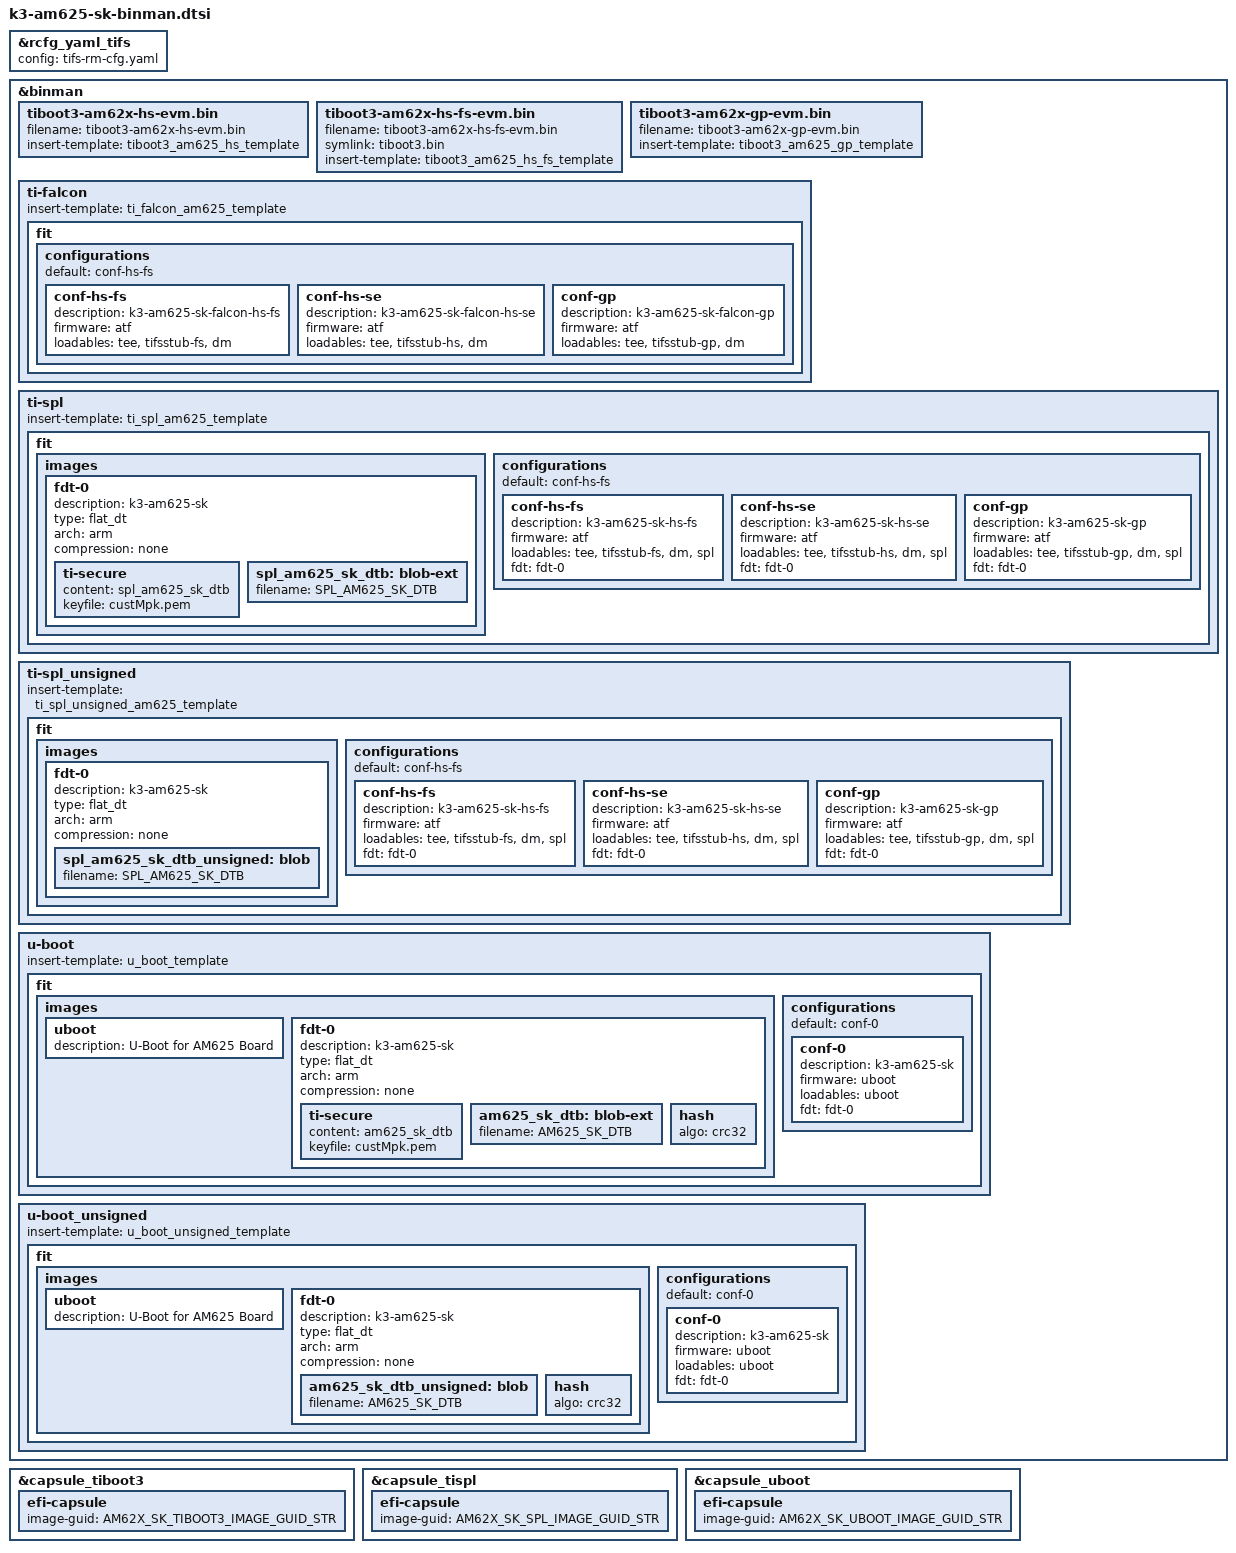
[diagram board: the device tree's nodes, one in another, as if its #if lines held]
// SPDX-License-Identifier: GPL-2.0
/*
 * Copyright (C) 2022-2023 Texas Instruments Incorporated - https://www.ti.com/
 */

#include "k3-am625-binman.dtsi"

#ifdef CONFIG_TARGET_AM625_R5_EVM

&rcfg_yaml_tifs {
	config = "tifs-rm-cfg.yaml";
};

&binman {
	tiboot3-am62x-hs-evm.bin {
		filename = "tiboot3-am62x-hs-evm.bin";
		insert-template = <&tiboot3_am625_hs_template>;
	};
	tiboot3-am62x-hs-fs-evm.bin {
		filename = "tiboot3-am62x-hs-fs-evm.bin";
		symlink = "tiboot3.bin";
		insert-template = <&tiboot3_am625_hs_fs_template>;
	};
	tiboot3-am62x-gp-evm.bin {
		filename = "tiboot3-am62x-gp-evm.bin";
		insert-template = <&tiboot3_am625_gp_template>;
	};
};

#include "k3-binman-capsule-r5.dtsi"

// Capsule update GUIDs in string form.  See am62x_evm.h
#define AM62X_SK_TIBOOT3_IMAGE_GUID_STR "abcb83d2-9cb6-4351-b8f1-6494bbe3700a"

&capsule_tiboot3 {
	efi-capsule {
		image-guid = AM62X_SK_TIBOOT3_IMAGE_GUID_STR;
	};
};

#endif

#ifdef CONFIG_TARGET_AM625_A53_EVM

#define SPL_AM625_SK_DTB "spl/dts/ti/k3-am625-sk.dtb"
#define AM625_SK_DTB "u-boot.dtb"

&binman {
	ti-falcon {
		insert-template = <&ti_falcon_am625_template>;
		fit {
			configurations {
				default = "conf-hs-fs";
				conf-hs-fs {
					description = "k3-am625-sk-falcon-hs-fs";
					firmware = "atf";
					loadables = "tee", "tifsstub-fs", "dm";
				};
				conf-hs-se {
					description = "k3-am625-sk-falcon-hs-se";
					firmware = "atf";
					loadables = "tee", "tifsstub-hs", "dm";
				};
				conf-gp {
					description = "k3-am625-sk-falcon-gp";
					firmware = "atf";
					loadables = "tee", "tifsstub-gp", "dm";
				};
			};
		};
	};

	ti-spl {
		insert-template = <&ti_spl_am625_template>;
		fit {
			images {
				fdt-0 {
					description = "k3-am625-sk";
					type = "flat_dt";
					arch = "arm";
					compression = "none";
					ti-secure {
						content = <&spl_am625_sk_dtb>;
						keyfile = "custMpk.pem";
					};
					spl_am625_sk_dtb: blob-ext {
						filename = SPL_AM625_SK_DTB;
					};
				};
			};
			configurations {
				default = "conf-hs-fs";
				conf-hs-fs {
					description = "k3-am625-sk-hs-fs";
					firmware = "atf";
					loadables = "tee", "tifsstub-fs", "dm", "spl";
					fdt = "fdt-0";
				};
				conf-hs-se {
					description = "k3-am625-sk-hs-se";
					firmware = "atf";
					loadables = "tee", "tifsstub-hs", "dm", "spl";
					fdt = "fdt-0";
				};
				conf-gp {
					description = "k3-am625-sk-gp";
					firmware = "atf";
					loadables = "tee", "tifsstub-gp", "dm", "spl";
					fdt = "fdt-0";
				};
			};
		};
	};

	ti-spl_unsigned {
		insert-template = <&ti_spl_unsigned_am625_template>;
		fit {
			images {
				fdt-0 {
					description = "k3-am625-sk";
					type = "flat_dt";
					arch = "arm";
					compression = "none";
					spl_am625_sk_dtb_unsigned: blob {
						filename = SPL_AM625_SK_DTB;
					};
				};
			};
			configurations {
				default = "conf-hs-fs";
				conf-hs-fs {
					description = "k3-am625-sk-hs-fs";
					firmware = "atf";
					loadables = "tee", "tifsstub-fs", "dm", "spl";
					fdt = "fdt-0";
				};
				conf-hs-se {
					description = "k3-am625-sk-hs-se";
					firmware = "atf";
					loadables = "tee", "tifsstub-hs", "dm", "spl";
					fdt = "fdt-0";
				};
				conf-gp {
					description = "k3-am625-sk-gp";
					firmware = "atf";
					loadables = "tee", "tifsstub-gp", "dm", "spl";
					fdt = "fdt-0";
				};
			};
		};
	};
};

&binman {
	u-boot {
		insert-template = <&u_boot_template>;

		fit {
			images {
				uboot {
					description = "U-Boot for AM625 Board";
				};

				fdt-0 {
					description = "k3-am625-sk";
					type = "flat_dt";
					arch = "arm";
					compression = "none";
					ti-secure {
						content = <&am625_sk_dtb>;
						keyfile = "custMpk.pem";
					};
					am625_sk_dtb: blob-ext {
						filename = AM625_SK_DTB;
					};
					hash {
						algo = "crc32";
					};
				};
			};

			configurations {
				default = "conf-0";

				conf-0 {
					description = "k3-am625-sk";
					firmware = "uboot";
					loadables = "uboot";
					fdt = "fdt-0";
				};

			};
		};
	};
};

&binman {
	u-boot_unsigned {
		insert-template = <&u_boot_unsigned_template>;

		fit {
			images {
				uboot {
					description = "U-Boot for AM625 Board";
				};

				fdt-0 {
					description = "k3-am625-sk";
					type = "flat_dt";
					arch = "arm";
					compression = "none";
					am625_sk_dtb_unsigned: blob {
						filename = AM625_SK_DTB;
					};
					hash {
						algo = "crc32";
					};
				};
			};

			configurations {
				default = "conf-0";

				conf-0 {
					description = "k3-am625-sk";
					firmware = "uboot";
					loadables = "uboot";
					fdt = "fdt-0";
				};
			};
		};
	};
};

#include "k3-binman-capsule.dtsi"

// Capsule update GUIDs in string form.  See am62x_evm.h
#define AM62X_SK_SPL_IMAGE_GUID_STR "aee355fc-bf97-4264-8c82-437255efdc1d"
#define AM62X_SK_UBOOT_IMAGE_GUID_STR "28ab8c6c-fca8-41d3-8ea1-5f171b7d2929"

&capsule_tispl {
	efi-capsule {
		image-guid = AM62X_SK_SPL_IMAGE_GUID_STR;
	};
};

&capsule_uboot {
	efi-capsule {
		image-guid = AM62X_SK_UBOOT_IMAGE_GUID_STR;
	};
};

#endif
